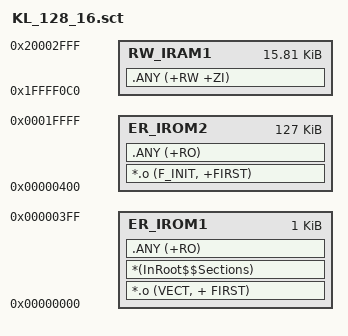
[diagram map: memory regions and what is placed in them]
;/* KL_128_16.ld                                                              */
;/* uVision memory file for the Kinetis KL - for use with the uTasker project */
;/* Use when running in FLASH (128k FLASH / 16k CPU SRAM)                     */

LR_IROM1 0x00000000 0x00000400  {    ; load region size_region
  ER_IROM1 0x00000000 0x00000400  {  ; load address = execution address
   *.o (VECT, + FIRST)
   *(InRoot$$Sections)
   .ANY (+RO)
  }
  RW_IRAM1 0x1FFFf0c0 0x00004000-0xc0  {  ; RW data
   .ANY (+RW +ZI)
  }
}

LR_IROM2 0x00000400 0x20000-0x400  {
  ER_IROM2 0x00000400 0x20000-0x400  {  ; load address = execution address
   *.o (F_INIT, +FIRST)
   .ANY (+RO)
  }
}
